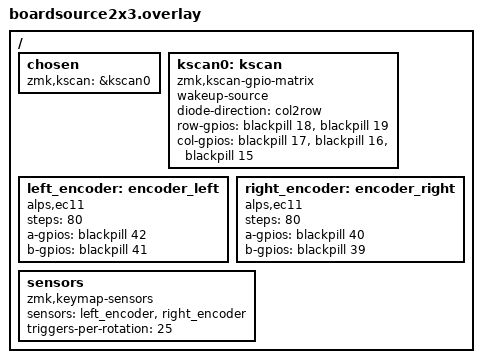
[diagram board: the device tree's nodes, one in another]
/*
 * Copyright (c) 2020 The ZMK Contributors
 *
 * SPDX-License-Identifier: MIT
 */

#include <dt-bindings/zmk/matrix_transform.h>

/ {
    chosen {
        zmk,kscan = &kscan0;
    };

    kscan0: kscan {
        compatible = "zmk,kscan-gpio-matrix";
        wakeup-source;

        diode-direction = "col2row";

        row-gpios
            = <&blackpill 18 (GPIO_ACTIVE_HIGH | GPIO_PULL_DOWN)>
            , <&blackpill 19 (GPIO_ACTIVE_HIGH | GPIO_PULL_DOWN)>
            ;

        col-gpios
            = <&blackpill 17 GPIO_ACTIVE_HIGH>
            , <&blackpill 16 GPIO_ACTIVE_HIGH>
            , <&blackpill 15 GPIO_ACTIVE_HIGH>
            ;
    };

    left_encoder: encoder_left {
        compatible = "alps,ec11";
        steps = <80>;
        a-gpios = <&blackpill 42 (GPIO_ACTIVE_HIGH | GPIO_PULL_UP)>;
        b-gpios = <&blackpill 41 (GPIO_ACTIVE_HIGH | GPIO_PULL_UP)>;
    };

    right_encoder: encoder_right {
        compatible = "alps,ec11";
        steps = <80>;
        a-gpios = <&blackpill 40 (GPIO_ACTIVE_HIGH | GPIO_PULL_UP)>;
        b-gpios = <&blackpill 39 (GPIO_ACTIVE_HIGH | GPIO_PULL_UP)>;
    };

    sensors: sensors {
        compatible = "zmk,keymap-sensors";
        sensors = <&left_encoder &right_encoder>;
        triggers-per-rotation = <25>;
    };
};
